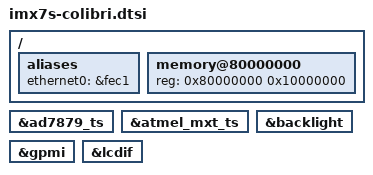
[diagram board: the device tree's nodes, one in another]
// SPDX-License-Identifier: GPL-2.0+ OR MIT
/*
 * Copyright 2016-2020 Toradex
 */

#include "imx7s.dtsi"
#include "imx7-colibri.dtsi"

/ {
        aliases {
                /* add ethernet aliases which is required to proprely pass mac
                   address from bootloader. Also with the update to 5.4.70-2.3.0
                   the kernel hangs without these aliases.
                 */
                ethernet0 = &fec1;
        };

	memory@80000000 {
		device_type = "memory";
		reg = <0x80000000 0x10000000>;
	};
};

&ad7879_ts {
	status = "okay";
};

&atmel_mxt_ts {
	status = "okay";
};

&backlight {
	status = "okay";
};

&gpmi {
	status = "okay";
};

&lcdif {
	status = "okay";
};
